AUTOSAR XML (schema 4-3-0)
package /cdd_uds
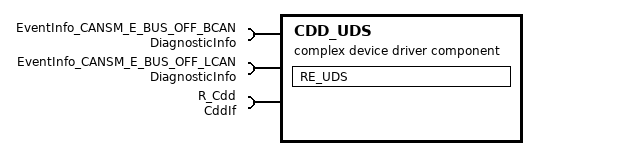
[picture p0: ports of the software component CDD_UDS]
  complex device driver sw component type CDD_UDS
    require port EventInfo_CANSM_E_BUS_OFF_BCAN: client-com-spec=GetEventStatus, required-interface=DiagnosticInfo
    require port EventInfo_CANSM_E_BUS_OFF_LCAN: client-com-spec=GetEventStatus, required-interface=DiagnosticInfo
    require port R_Cdd: client-com-spec=ClearDTC, required-interface=CddIf
    behavior InternalBehavior
      runnable RE_UDS: can-be-invoked-concurrently=true
        sync call SSCP_RE_UDS_EventInfo_CANSM_E_BUS_OFF_BCAN_GetEventStatus: operation=EventInfo_CANSM_E_BUS_OFF_BCAN.GetEventStatus
        sync call SSCP_RE_UDS_EventInfo_CANSM_E_BUS_OFF_LCAN_GetEventStatus: operation=EventInfo_CANSM_E_BUS_OFF_LCAN.GetEventStatus
        sync call SSCP_RE_UDS_R_Cdd_ClearDTC: operation=R_Cdd.ClearDTC
